# ABE_PRM register map
Vendor: Texas Instruments
Peripheral module from a debugger description file (folder omap5430_ES2_PUBLIC).
Registers are 32-bit, access not given, reset 0x0 unless marked. A register's access mark holds for its fields unless they carry their own. Offsets are as the file gives them; lines under a group give offsets from that group; [hi:lo] are bit positions; {n}, {i} and the like mark numbered series; 'fields as' and 'values as' point back to an identical list; <NAME> marks a mode.

## ABE_PRM
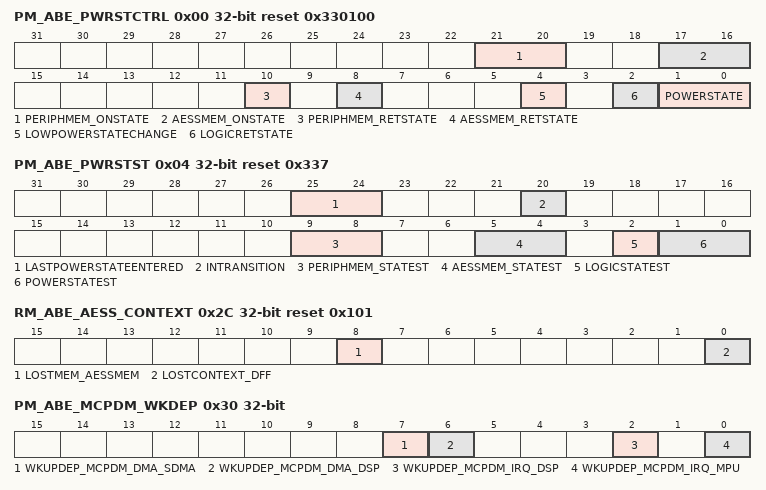
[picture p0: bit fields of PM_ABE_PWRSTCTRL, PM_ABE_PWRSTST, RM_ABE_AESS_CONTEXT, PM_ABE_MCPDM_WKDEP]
0x00 PM_ABE_PWRSTCTRL reset 0x330100 — This register controls the ABE domain power state to reach upon a domain sleep transition
  [21:20] PERIPHMEM_ONSTATE ro — PERIPHMEM memory state when domain is ON.
    3=Mem_on (Memory bank is on when the domain is ON.)
  [17:16] AESSMEM_ONSTATE ro — AESSMEM memory state when domain is ON.
    3=Mem_on (Memory bank is on when the domain is ON.)
  [10] PERIPHMEM_RETSTATE ro — PERIPHMEM memory state when domain is RETENTION.
    0=mem_off (Memory bank is off when the domain is in the RETENTION state.)
  [8] AESSMEM_RETSTATE ro — AESSMEM memory state when domain is RETENTION.
    1=mem_ret (Memory bank is retained when domain is in RETENTION state.)
  [4] LOWPOWERSTATECHANGE — Power state change request when domain has already performed a sleep transition. Allows going into deeper low power state without waking up the power domain. (access RW WSpecial)
    0=DIS (Do not request a low power state change.); 1=EN (Request a low power state change. This bit is automatically cleared when the power state is effectively changed or when power state is ON.)
  [2] LOGICRETSTATE ro — Logic state when power domain is RETENTION
    0=logic_off (Whole logic is off when the domain is in RETENTION state.)
  [1:0] POWERSTATE rw — Power state control
    0=OFF (Reserved); 1=RET (RETENTION state); 2=INACT (INACTIVE state); 3=ON (ON State)
0x04 PM_ABE_PWRSTST reset 0x337 — This register provides a status on the ABE domain current power domain state. [warm reset insensitive]
  [25:24] LASTPOWERSTATEENTERED — Last low power state entered. Set to 0x3 upon write of the same only. This register is intended for debug purpose only. (access RW W1toSet)
    3=ON (Power domain was previously ON-ACTIVE); 2=INACTIVE (Power domain was previously ON-INACTIVE); 1=RET (Power domain was previously in RETENTION); 0=OFF (Reserved)
  [20] INTRANSITION ro — Domain transition status
    0=No (No on-going transition on power domain); 1=Ongoing (Power domain transition is in progress.)
  [9:8] PERIPHMEM_STATEST ro — PERIPHMEM memory state status
    0=Mem_off (Reserved); 3=Mem_on (Memory is ON)
  [5:4] AESSMEM_STATEST ro — AESSMEM memory state status
    0=Mem_off (Reserved); 1=Mem_ret (Memory is RETENTION); 3=Mem_on (Memory is ON)
  [2] LOGICSTATEST ro — Logic state status
    0=OFF (Logic in domain is OFF); 1=ON (Logic in domain is ON)
  [1:0] POWERSTATEST ro — Current power state status
    0=OFF (Reserved); 1=RET (Power domain is in RETENTION); 2=INACTIVE (Power domain is ON-INACTIVE); 3=ON (Power domain is ON-ACTIVE)
0x2C RM_ABE_AESS_CONTEXT reset 0x101 — This register contains dedicated AESS context statuses. [warm reset insensitive]
  [8] LOSTMEM_AESSMEM — Specify if memory-based context in AESSMEM memory bank has been lost due to a previous power transition or other reset source. (access RW W1toClr)
    0=Maintained (Context has been maintained); 1=Lost (Context has been lost)
  [0] LOSTCONTEXT_DFF — Specify if DFF-based context has been lost due to a previous power transition or other reset source. (set upon assertion of ABE_RST signal) (access RW W1toClr)
    values as LOSTMEM_AESSMEM
0x30 PM_ABE_MCPDM_WKDEP access per field — This register controls wakeup dependency based on McPDM service requests.
  [all] fields
    0=Disabled (Dependency is disabled); 1=Enabled (Dependency is enabled)
  [7] WKUPDEP_MCPDM_DMA_SDMA rw — Wakeup dependency from McPDM module (SWakeup_dma signal) towards DMA_SYSTEM + L3_MAIN2 + L3_MAIN1 domains
  [6] WKUPDEP_MCPDM_DMA_DSP rw — Wakeup dependency from McPDM module (SWakeup_dma signal) towards DSP domain
  [2] WKUPDEP_MCPDM_IRQ_DSP rw — Wakeup dependency from McPDM module (SWakeup_irq signal) towards DSP domain
  [0] WKUPDEP_MCPDM_IRQ_MPU rw — Wakeup dependency from McPDM module (SWakeup_irq signal) towards MPU domain
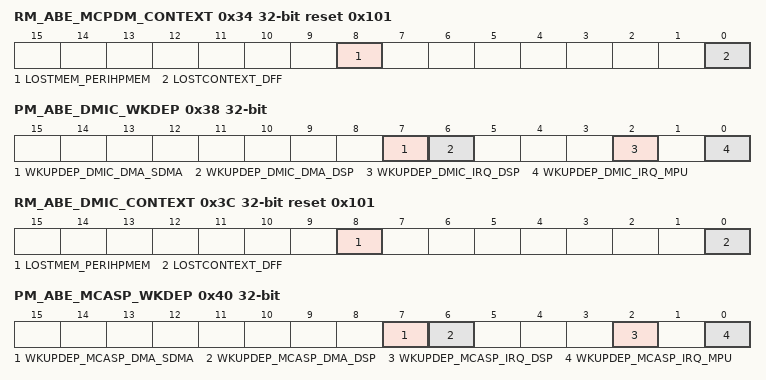
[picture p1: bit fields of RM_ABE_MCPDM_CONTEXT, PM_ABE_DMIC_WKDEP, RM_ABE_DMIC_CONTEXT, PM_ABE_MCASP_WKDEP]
0x34 RM_ABE_MCPDM_CONTEXT reset 0x101 — This register contains dedicated McPDM context statuses. [warm reset insensitive]
  [8] LOSTMEM_PERIHPMEM — Specify if memory-based context in PERIHPMEM memory bank has been lost due to a previous power transition or other reset source. (access RW W1toClr)
    values as RM_ABE_AESS_CONTEXT.LOSTMEM_AESSMEM
  [0] LOSTCONTEXT_DFF — Specify if DFF-based context has been lost due to a previous power transition or other reset source. (set upon assertion of ABE_RST signal) (access RW W1toClr)
    values as RM_ABE_AESS_CONTEXT.LOSTMEM_AESSMEM
0x38 PM_ABE_DMIC_WKDEP access per field — This register controls wakeup dependency based on DMIC service requests.
  [all] fields
    values as the fields of PM_ABE_MCPDM_WKDEP
  [7] WKUPDEP_DMIC_DMA_SDMA rw — Wakeup dependency from DMIC module (SWakeup_dma signal) towards DMA_SYSTEM + L3_MAIN2 + L3_MAIN1 domains
  [6] WKUPDEP_DMIC_DMA_DSP rw — Wakeup dependency from DMIC module (SWakeup_dma signal) towards DSP domain
  [2] WKUPDEP_DMIC_IRQ_DSP rw — Wakeup dependency from DMIC module (SWakeup_irq signal) towards DSP domain
  [0] WKUPDEP_DMIC_IRQ_MPU rw — Wakeup dependency from DMIC module (SWakeup_irq signal) towards MPU domain
0x3C RM_ABE_DMIC_CONTEXT reset 0x101 — This register contains dedicated DMIC context statuses. [warm reset insensitive]
  fields as RM_ABE_MCPDM_CONTEXT
0x40 PM_ABE_MCASP_WKDEP access per field — This register controls wakeup dependency based on MCASP service requests.
  [all] fields
    values as the fields of PM_ABE_MCPDM_WKDEP
  [7] WKUPDEP_MCASP_DMA_SDMA rw — Wakeup dependency from MCASP module (SWakeup_dma signal) towards DMA_SYSTEM + L3_MAIN2 + L3_MAIN1 domains
  [6] WKUPDEP_MCASP_DMA_DSP rw — Wakeup dependency from MCASP module (SWakeup_dma signal) towards DSP domain
  [2] WKUPDEP_MCASP_IRQ_DSP rw — Wakeup dependency from MCASP module (SWakeup_irq signal) towards DSP domain
  [0] WKUPDEP_MCASP_IRQ_MPU rw — Wakeup dependency from MCASP module (SWakeup_irq signal) towards MPU domain
0x44 RM_ABE_MCASP_CONTEXT reset 0x1 — This register contains dedicated MCASP context statuses. [warm reset insensitive]
  [0] LOSTCONTEXT_DFF — Specify if DFF-based context has been lost due to a previous power transition or other reset source. (set upon assertion of ABE_RST signal) (access RW W1toClr)
    values as RM_ABE_AESS_CONTEXT.LOSTMEM_AESSMEM
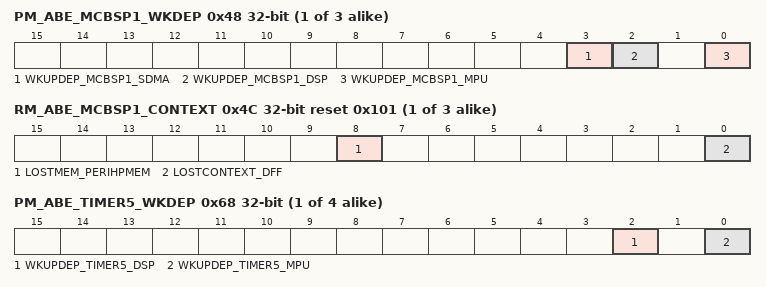
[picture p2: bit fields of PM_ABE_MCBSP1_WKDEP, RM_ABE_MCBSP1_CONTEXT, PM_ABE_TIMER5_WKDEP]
{0x40+8i} PM_ABE_MCBSP{i}_WKDEP access per field (i=1..3) — This register controls wakeup dependency based on MCBSP{i} service requests.
  [all] fields
    values as the fields of PM_ABE_MCPDM_WKDEP
  [3] WKUPDEP_MCBSP{i}_SDMA rw — Wakeup dependency from MCBSP{i} module (SWakeup signal) towards DMA_SYSTEM + L3_MAIN2 + L3_MAIN1 domains
  [2] WKUPDEP_MCBSP{i}_DSP rw — Wakeup dependency from MCBSP{i} module (SWakeup signal) towards DSP domain
  [0] WKUPDEP_MCBSP{i}_MPU rw — Wakeup dependency from MCBSP{i} module (SWakeup signal) towards MPU domain
{0x44+8i} RM_ABE_MCBSP{i}_CONTEXT reset 0x101 (i=1..3) — This register contains dedicated MCBSP{i} context statuses. [warm reset insensitive]
  fields as RM_ABE_MCPDM_CONTEXT
{0x40+8i} PM_ABE_TIMER{i}_WKDEP access per field (i=5..8) — This register controls wakeup dependency based on TIMER{i} service requests.
  [2] WKUPDEP_TIMER{i}_DSP rw — Wakeup dependency from TIMER{i} module (SWakeup signal) towards DSP domain
    values as the fields of PM_ABE_MCPDM_WKDEP
  [0] WKUPDEP_TIMER{i}_MPU rw — Wakeup dependency from TIMER{i} module (SWakeup signal) towards MPU domain
    values as the fields of PM_ABE_MCPDM_WKDEP
{0x44+8i} RM_ABE_TIMER{i}_CONTEXT reset 0x1 (i=5..8) — This register contains dedicated TIMER{i} context statuses. [warm reset insensitive]
  fields as RM_ABE_MCASP_CONTEXT
0x88 PM_ABE_WD_TIMER3_WKDEP access per field reset 0x1 — This register controls wakeup dependency based on WD_TIMER3 service requests.
  [0] WKUPDEP_WD_TIMER3_MPU rw — Wakeup dependency from WD_TIMER3 module (SWakeup signal) towards MPU domain
    values as the fields of PM_ABE_MCPDM_WKDEP
0x8C RM_ABE_WD_TIMER3_CONTEXT reset 0x1 — This register contains dedicated WD_TIMER3 context statuses. [warm reset insensitive]
  fields as RM_ABE_MCASP_CONTEXT
